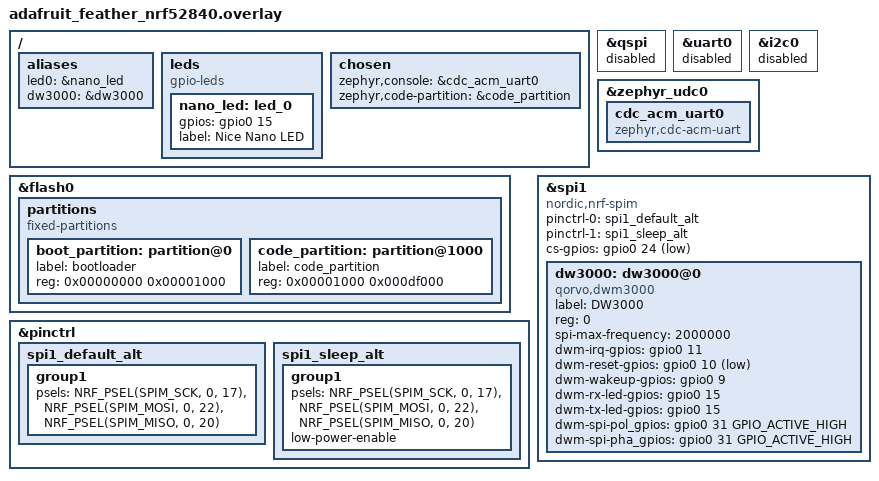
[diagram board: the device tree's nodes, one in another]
/* GEREKLİ KÜTÜPHANELER */
#include <zephyr/dt-bindings/pinctrl/nrf-pinctrl.h>
#include <zephyr/dt-bindings/gpio/gpio.h>

/ {
    aliases {
        led0 = &nano_led;
        dw3000 = &dw3000;
    };

    leds {
        compatible = "gpio-leds";
        nano_led: led_0 {
            gpios = <&gpio0 15 GPIO_ACTIVE_HIGH>;
            label = "Nice Nano LED";
        };
    };
    
    chosen {
        zephyr,console = &cdc_acm_uart0;
        zephyr,code-partition = &code_partition;
    };
};

/* --- KULLANILMAYAN DONANIMLARI KAPAT --- */
&qspi { status = "disabled"; };
&uart0 { status = "disabled"; };
&i2c0 { status = "disabled"; };

/* --- HAFIZAYI 0x1000 ADRESİNE KAYDIR --- */
&flash0 {
    /delete-node/ partitions;
    partitions {
        compatible = "fixed-partitions";
        #address-cells = <1>;
        #size-cells = <1>;

        boot_partition: partition@0 {
            label = "bootloader";
            reg = <0x00000000 0x00001000>;
        };
        code_partition: partition@1000 {
            label = "code_partition";
            reg = <0x00001000 0x000df000>;
        };
    };
};

/* --- USB DONANIMI --- */
&zephyr_udc0 {
    status = "okay";
    cdc_acm_uart0: cdc_acm_uart0 {
        compatible = "zephyr,cdc-acm-uart";
    };
};

/* --- SPI PİNLERİ (0.17, 0.20, 0.22) --- */
&pinctrl {
    spi1_default_alt: spi1_default_alt {
        group1 {
            psels = <NRF_PSEL(SPIM_SCK, 0, 17)>,
                    <NRF_PSEL(SPIM_MOSI, 0, 22)>,
                    <NRF_PSEL(SPIM_MISO, 0, 20)>;
        };
    };

    spi1_sleep_alt: spi1_sleep_alt {
        group1 {
            psels = <NRF_PSEL(SPIM_SCK, 0, 17)>,
                    <NRF_PSEL(SPIM_MOSI, 0, 22)>,
                    <NRF_PSEL(SPIM_MISO, 0, 20)>;
            low-power-enable;
        };
    };
};

/* --- SPI VE UWB MODÜLÜ --- */
&spi1 {
    compatible = "nordic,nrf-spim";
    status = "okay";
    
    #address-cells = <1>;
    #size-cells = <0>;
    
    pinctrl-0 = <&spi1_default_alt>;
    pinctrl-1 = <&spi1_sleep_alt>;
    pinctrl-names = "default", "sleep";
    
    cs-gpios = <&gpio0 24 (GPIO_ACTIVE_LOW | GPIO_PULL_UP)>; /* 0.24 Pini */

    dw3000: dw3000@0 {
        compatible = "qorvo,dwm3000";
        label = "DW3000";
        reg = <0>;
        spi-max-frequency = <2000000>;
        
        /* GERÇEK VE HAYATİ BAĞLANTILAR (Kabloladığın pinler) */
        dwm-irq-gpios    = <&gpio0 11 (GPIO_ACTIVE_HIGH | GPIO_PULL_DOWN)>; 
        dwm-reset-gpios  = <&gpio0 10 (GPIO_ACTIVE_LOW | GPIO_PULL_UP)>;    
        dwm-wakeup-gpios = <&gpio0 9 GPIO_ACTIVE_HIGH>;                     
        
        /* ZEPHYR'İ KANDIRMAK İÇİN ZORUNLU GÖSTERİLEN (AMA KULLANILMAYACAK) PİNLER */
        dwm-rx-led-gpios = <&gpio0 15 GPIO_ACTIVE_HIGH>; /* SuperMini'nin kendi üzerindeki Mavi LED */
        dwm-tx-led-gpios = <&gpio0 15 GPIO_ACTIVE_HIGH>; /* Aynı LED'i iki kere kullandık :) */
        dwm-spi-pol_gpios = <&gpio0 31 GPIO_ACTIVE_HIGH>; /* Boşta duran rastgele bir pin */
        dwm-spi-pha_gpios = <&gpio0 31 GPIO_ACTIVE_HIGH>; /* Boşta duran rastgele bir pin */
        
        status = "okay";
    };
};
